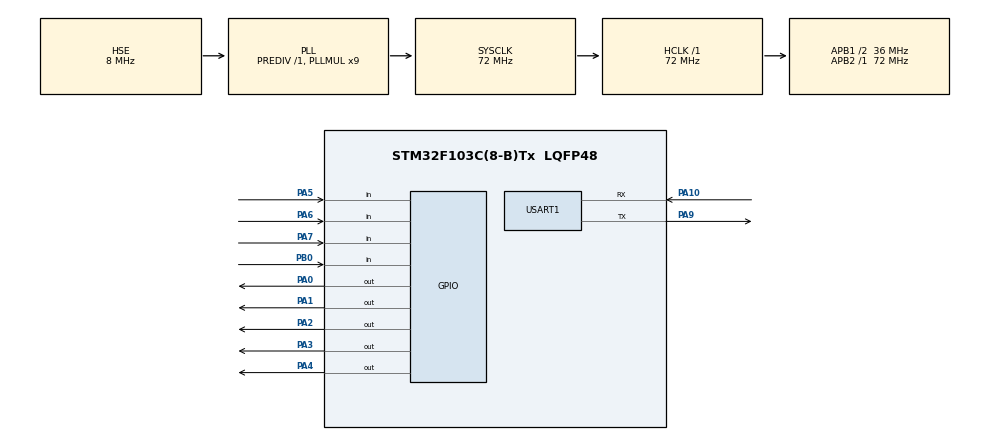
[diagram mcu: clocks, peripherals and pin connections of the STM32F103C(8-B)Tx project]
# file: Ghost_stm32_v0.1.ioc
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Mcu.Family=STM32F1
RCC.PLLSourceVirtual=RCC_PLLSOURCE_HSE
PD1-OSC_OUT.Mode=HSE-External-Oscillator
PA10.Mode=Asynchronous
NVIC.TIM1_UP_IRQn=true\:0\:0\:false\:false\:true\:true\:true
PD0-OSC_IN.Signal=RCC_OSC_IN
RCC.APB1CLKDivider=RCC_HCLK_DIV2
RCC.SYSCLKSource=RCC_SYSCLKSOURCE_PLLCLK
ProjectManager.StackSize=0x400
PA0-WKUP.Signal=GPIO_Output
PD1-OSC_OUT.Signal=RCC_OSC_OUT
PA13.Signal=SYS_JTMS-SWDIO
PA9.Mode=Asynchronous
ProjectManager.TargetToolchain=MDK-ARM V5.27
RCC.HCLKFreq_Value=72000000
RCC.APB2TimFreq_Value=72000000
PA9.Signal=USART1_TX
RCC.USBFreq_Value=72000000
PA7.GPIO_PuPd=GPIO_PULLDOWN
PA1.Signal=GPIO_Output
RCC.AHBFreq_Value=72000000
PD0-OSC_IN.Mode=HSE-External-Oscillator
PA5.Signal=GPIO_Input
board=custom
RCC.PLLMUL=RCC_PLL_MUL9
RCC.APB2Freq_Value=72000000
PA6.GPIO_PuPd=GPIO_PULLDOWN
PA14.Mode=Serial_Wire
PA5.GPIO_PuPd=GPIO_PULLDOWN
PA13.Mode=Serial_Wire
Mcu.Name=STM32F103C(8-B)Tx
VP_TIM1_VS_ClockSourceINT.Mode=Internal
PA2.Signal=GPIO_Output
PA4.Signal=GPIO_Output
RCC.SYSCLKFreq_VALUE=72000000
Mcu.Package=LQFP48
PA6.Signal=GPIO_Input
USART1.VirtualMode=VM_ASYNC
PA10.Signal=USART1_RX
PA14.Signal=SYS_JTCK-SWCLK
ProjectManager.HeapSize=0x200
NVIC.PriorityGroup=NVIC_PRIORITYGROUP_4
RCC.APB1TimFreq_Value=72000000
NVIC.USART1_IRQn=true\:0\:0\:false\:false\:true\:true\:true
RCC.APB1Freq_Value=36000000
PB0.Signal=GPIO_Input
PB0.GPIO_PuPd=GPIO_PULLDOWN
PA3.Signal=GPIO_Output
PA7.Signal=GPIO_Input

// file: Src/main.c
/* USER CODE BEGIN Header */
/**
  ******************************************************************************
  * @file           : main.c
  * @brief          : Main program body
  ******************************************************************************
  * @attention
  *
  * <h2><center>&copy; Copyright (c) 2020 STMicroelectronics.
  * All rights reserved.</center></h2>
  *
  * This software component is licensed by ST under BSD 3-Clause license,
  * the "License"; You may not use this file except in compliance with the
  * License. You may obtain a copy of the License at:
  *                        opensource.org/licenses/BSD-3-Clause
  *
  ******************************************************************************
  */
/* USER CODE END Header */

#include "main.h"
#include "tim.h"
#include "usart.h"
#include "gpio.h"

/* USER CODE BEGIN Includes */
#include "kbd_serial.h"
#include "kbd_info.h"
#include "kbd_scan.h"
#include "kbd_report.h"
/* USER CODE END Includes */

void SystemClock_Config(void);

int main(void)
{
  /* USER CODE BEGIN 1 */
  extern kbd_ans_t* ans;
  /* USER CODE END 1 */

  /* MCU Configuration--------------------------------------------------------*/

  /* Reset of all peripherals, Initializes the Flash interface and the Systick. */
  HAL_Init();

  /* Configure the system clock */
  SystemClock_Config();

  /* Initialize all configured peripherals */
  MX_GPIO_Init();
  MX_TIM1_Init();
  MX_USART1_UART_Init();

  /* Infinite loop */
  /* USER CODE BEGIN WHILE */
	KBD_SCAN_ANS_INIT();
  //test();
  while (1)
  {
		//KBD_ANS_INIT();
		// uint8_t hello[]="hello\n";
		// HAL_UART_Transmit(&huart1,hello,sizeof(hello),100);
    KBD_SCAN_MAIN();

    /* USER CODE END WHILE */

    /* USER CODE BEGIN 3 */
    HAL_Delay(10);
  }
  /* USER CODE END 3 */
}

void SystemClock_Config(void)
{
  RCC_OscInitTypeDef RCC_OscInitStruct = {0};
  RCC_ClkInitTypeDef RCC_ClkInitStruct = {0};

  /** Initializes the CPU, AHB and APB busses clocks
  */
  RCC_OscInitStruct.OscillatorType = RCC_OSCILLATORTYPE_HSE;
  RCC_OscInitStruct.HSEState = RCC_HSE_ON;
  RCC_OscInitStruct.HSEPredivValue = RCC_HSE_PREDIV_DIV1;
  RCC_OscInitStruct.HSIState = RCC_HSI_ON;
  RCC_OscInitStruct.PLL.PLLState = RCC_PLL_ON;
  RCC_OscInitStruct.PLL.PLLSource = RCC_PLLSOURCE_HSE;
  RCC_OscInitStruct.PLL.PLLMUL = RCC_PLL_MUL9;
  if (HAL_RCC_OscConfig(&RCC_OscInitStruct) != HAL_OK)
  {
    Error_Handler();
  }
  /** Initializes the CPU, AHB and APB busses clocks
  */
  RCC_ClkInitStruct.ClockType = RCC_CLOCKTYPE_HCLK|RCC_CLOCKTYPE_SYSCLK
                              |RCC_CLOCKTYPE_PCLK1|RCC_CLOCKTYPE_PCLK2;
  RCC_ClkInitStruct.SYSCLKSource = RCC_SYSCLKSOURCE_PLLCLK;
  RCC_ClkInitStruct.AHBCLKDivider = RCC_SYSCLK_DIV1;
  RCC_ClkInitStruct.APB1CLKDivider = RCC_HCLK_DIV2;
  RCC_ClkInitStruct.APB2CLKDivider = RCC_HCLK_DIV1;

  if (HAL_RCC_ClockConfig(&RCC_ClkInitStruct, FLASH_LATENCY_2) != HAL_OK)
  {
    Error_Handler();
  }
}

void Error_Handler(void)
{
}

/************************ (C) COPYRIGHT STMicroelectronics *****END OF FILE****/
